AUTOSAR XML (schema 4-2-2)
package /ComponentTypes
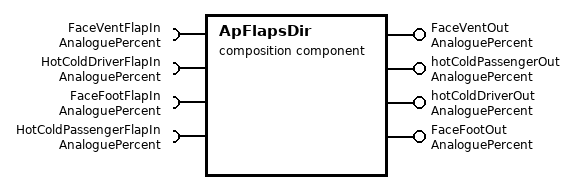
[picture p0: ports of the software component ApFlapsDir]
  composition sw component type ApFlapsDir
    4 x require port, all with required-interface=AnaloguePercent:
      FaceVentFlapIn
      HotColdDriverFlapIn
      FaceFootFlapIn
      HotColdPassengerFlapIn
    4 x provide port, all with provided-interface=AnaloguePercent:
      FaceVentOut
      hotColdPassengerOut
      hotColdDriverOut
      FaceFootOut
    component AirMixIn: type=AirMixIn
    component AirMixOut: type=AirMixOut
    delegate AirMixOut.InputPercentageStepper <-> outer port HotColdPassengerFlapIn
    delegate AirMixOut.InputPercentageStepper <-> outer port FaceFootFlapIn
    delegate AirMixOut.InputPercentageStepper <-> outer port HotColdDriverFlapIn
    delegate AirMixOut.InputPercentageStepper <-> outer port FaceVentFlapIn
    delegate AirMixIn.FlapSettingPercent <-> outer port FaceFootOut
    delegate AirMixIn.FlapSettingPercent <-> outer port hotColdDriverOut
    delegate AirMixIn.FlapSettingPercent <-> outer port hotColdPassengerOut
    delegate AirMixIn.FlapSettingPercent <-> outer port FaceVentOut
